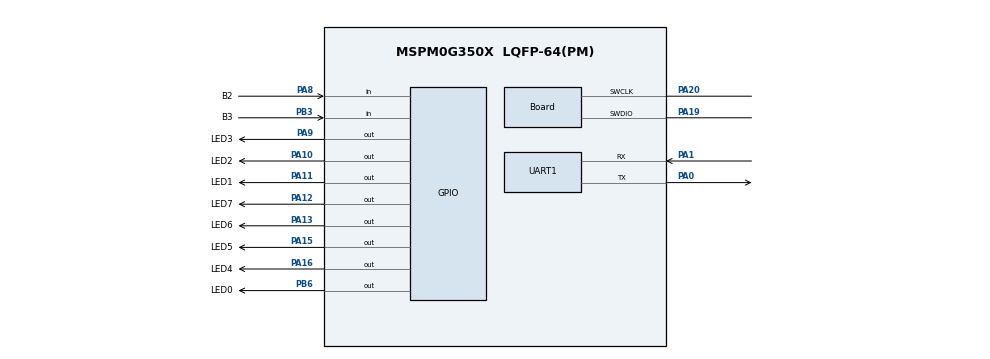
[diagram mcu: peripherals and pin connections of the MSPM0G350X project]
/**
 * @cliArgs --device "MSPM0G350X" --part "Default" --package "LQFP-64(PM)" --product "mspm0_sdk@2.05.01.01"
 * @versions {"tool":"1.24.0+4110"}
 */

/**
 * Import the modules used in this configuration.
 */
const ADC12  = scripting.addModule("/ti/driverlib/ADC12", {}, false);
const ADC121 = ADC12.addInstance();
const GPIO   = scripting.addModule("/ti/driverlib/GPIO", {}, false);
const GPIO1  = GPIO.addInstance();
const GPIO2  = GPIO.addInstance();
const SYSCTL = scripting.addModule("/ti/driverlib/SYSCTL");
const TIMER  = scripting.addModule("/ti/driverlib/TIMER", {}, false);
const TIMER1 = TIMER.addInstance();
const UART   = scripting.addModule("/ti/driverlib/UART", {}, false);
const UART1  = UART.addInstance();

/**
 * Write custom configuration values to the imported modules.
 */
ADC121.$name                             = "ADC12_0";
ADC121.adcMem1chansel                    = "DL_ADC12_INPUT_CHAN_1";
ADC121.adcMem2chansel                    = "DL_ADC12_INPUT_CHAN_2";
ADC121.adcMem3chansel                    = "DL_ADC12_INPUT_CHAN_3";
ADC121.adcMem4chansel                    = "DL_ADC12_INPUT_CHAN_5";
ADC121.adcMem5chansel                    = "DL_ADC12_INPUT_CHAN_6";
ADC121.adcMem6chansel                    = "DL_ADC12_INPUT_CHAN_7";
ADC121.adcMem7chansel                    = "DL_ADC12_INPUT_CHAN_12";
ADC121.repeatMode                        = true;
ADC121.powerDownMode                     = "DL_ADC12_POWER_DOWN_MODE_MANUAL";
ADC121.configureDMA                      = true;
ADC121.enabledInterrupts                 = ["DL_ADC12_INTERRUPT_DMA_DONE"];
ADC121.samplingOperationMode             = "sequence";
ADC121.sampleTime0                       = "100ns";
ADC121.endAdd                            = 7;
ADC121.enableFIFO                        = true;
ADC121.sampCnt                           = 2;
ADC121.enabledDMATriggers                = ["DL_ADC12_DMA_MEM11_RESULT_LOADED","DL_ADC12_DMA_MEM3_RESULT_LOADED","DL_ADC12_DMA_MEM7_RESULT_LOADED"];
ADC121.trigSrc                           = "DL_ADC12_TRIG_SRC_EVENT";
ADC121.adcMem7trig                       = "DL_ADC12_TRIGGER_MODE_TRIGGER_NEXT";
ADC121.subChanID                         = 1;
ADC121.adcPin0Config.$name               = "ti_driverlib_gpio_GPIOPinGeneric2";
ADC121.DMA_CHANNEL.$name                 = "DMA_CH0";
ADC121.DMA_CHANNEL.configureTransferSize = true;
ADC121.DMA_CHANNEL.transferMode          = "FULL_CH_REPEAT_SINGLE";
ADC121.DMA_CHANNEL.addressMode           = "f2b";
ADC121.DMA_CHANNEL.transferSize          = 480;
ADC121.DMA_CHANNEL.peripheral.$assign    = "DMA_CH0";
ADC121.peripheral.$assign                = "ADC0";
ADC121.peripheral.adcPin0.$assign        = "PA27";
ADC121.peripheral.adcPin1.$assign        = "PA26";
ADC121.peripheral.adcPin2.$assign        = "PA25";
ADC121.peripheral.adcPin3.$assign        = "PA24";
ADC121.peripheral.adcPin5.$assign        = "PB24";
ADC121.peripheral.adcPin6.$assign        = "PB20";
ADC121.peripheral.adcPin7.$assign        = "PA22";
ADC121.peripheral.adcPin12.$assign       = "PA14";
ADC121.adcPin1Config.$name               = "ti_driverlib_gpio_GPIOPinGeneric3";
ADC121.adcPin2Config.$name               = "ti_driverlib_gpio_GPIOPinGeneric4";
ADC121.adcPin3Config.$name               = "ti_driverlib_gpio_GPIOPinGeneric5";
ADC121.adcPin5Config.$name               = "ti_driverlib_gpio_GPIOPinGeneric6";
ADC121.adcPin6Config.$name               = "ti_driverlib_gpio_GPIOPinGeneric7";
ADC121.adcPin7Config.$name               = "ti_driverlib_gpio_GPIOPinGeneric8";
ADC121.adcPin12Config.$name              = "ti_driverlib_gpio_GPIOPinGeneric9";

const Board                       = scripting.addModule("/ti/driverlib/Board", {}, false);
Board.peripheral.$assign          = "DEBUGSS";
Board.peripheral.swclkPin.$assign = "PA20";
Board.peripheral.swdioPin.$assign = "PA19";

GPIO1.$name                              = "KEY";
GPIO1.associatedPins.create(3);
GPIO1.associatedPins[0].$name            = "B2";
GPIO1.associatedPins[0].direction        = "INPUT";
GPIO1.associatedPins[0].assignedPort     = "PORTA";
GPIO1.associatedPins[0].assignedPin      = "8";
GPIO1.associatedPins[0].internalResistor = "PULL_UP";
GPIO1.associatedPins[0].pin.$assign      = "PA8";
GPIO1.associatedPins[1].$name            = "B3";
GPIO1.associatedPins[1].direction        = "INPUT";
GPIO1.associatedPins[1].internalResistor = "PULL_UP";
GPIO1.associatedPins[1].assignedPort     = "PORTB";
GPIO1.associatedPins[1].assignedPin      = "3";
GPIO1.associatedPins[1].pin.$assign      = "PB3";
GPIO1.associatedPins[2].$name            = "PB21";
GPIO1.associatedPins[2].direction        = "INPUT";
GPIO1.associatedPins[2].assignedPort     = "PORTB";
GPIO1.associatedPins[2].assignedPin      = "21";
GPIO1.associatedPins[2].internalResistor = "PULL_UP";

GPIO2.$name                          = "LED";
GPIO2.associatedPins.create(9);
GPIO2.associatedPins[0].$name        = "LED0";
GPIO2.associatedPins[0].assignedPort = "PORTB";
GPIO2.associatedPins[0].assignedPin  = "6";
GPIO2.associatedPins[0].pin.$assign  = "PB6";
GPIO2.associatedPins[1].$name        = "LED1";
GPIO2.associatedPins[1].assignedPort = "PORTA";
GPIO2.associatedPins[1].assignedPin  = "11";
GPIO2.associatedPins[1].pin.$assign  = "PA11";
GPIO2.associatedPins[2].assignedPort = "PORTA";
GPIO2.associatedPins[2].$name        = "LED2";
GPIO2.associatedPins[2].assignedPin  = "10";
GPIO2.associatedPins[2].pin.$assign  = "PA10";
GPIO2.associatedPins[3].$name        = "LED3";
GPIO2.associatedPins[3].assignedPort = "PORTA";
GPIO2.associatedPins[3].assignedPin  = "9";
GPIO2.associatedPins[3].pin.$assign  = "PA9";
GPIO2.associatedPins[4].$name        = "LED4";
GPIO2.associatedPins[4].assignedPort = "PORTA";
GPIO2.associatedPins[4].assignedPin  = "16";
GPIO2.associatedPins[4].pin.$assign  = "PA16";
GPIO2.associatedPins[5].$name        = "LED5";
GPIO2.associatedPins[5].assignedPort = "PORTA";
GPIO2.associatedPins[5].assignedPin  = "15";
GPIO2.associatedPins[5].pin.$assign  = "PA15";
GPIO2.associatedPins[6].$name        = "LED6";
GPIO2.associatedPins[6].assignedPort = "PORTA";
GPIO2.associatedPins[6].assignedPin  = "13";
GPIO2.associatedPins[6].pin.$assign  = "PA13";
GPIO2.associatedPins[7].$name        = "LED7";
GPIO2.associatedPins[7].assignedPort = "PORTA";
GPIO2.associatedPins[7].assignedPin  = "12";
GPIO2.associatedPins[7].pin.$assign  = "PA12";
GPIO2.associatedPins[8].$name        = "PB22";
GPIO2.associatedPins[8].assignedPort = "PORTB";
GPIO2.associatedPins[8].assignedPin  = "22";

SYSCTL.forceDefaultClkConfig = true;
SYSCTL.peripheral.$assign    = "SYSCTL";

TIMER1.$name                       = "TIMER_0";
TIMER1.timerMode                   = "PERIODIC";
TIMER1.timerStartTimer             = true;
TIMER1.event1PublisherChannel      = 1;
TIMER1.event1ControllerInterruptEn = ["ZERO_EVENT"];
TIMER1.timerPeriod                 = "2ms";
TIMER1.peripheral.$assign          = "TIMA0";

UART1.$name                    = "UART_0";
UART1.enabledInterrupts        = ["RX"];
UART1.uartClkDiv               = "8";
UART1.peripheral.$assign       = "UART0";
UART1.peripheral.rxPin.$assign = "PA1";
UART1.peripheral.txPin.$assign = "PA0";
UART1.txPinConfig.$name        = "ti_driverlib_gpio_GPIOPinGeneric0";
UART1.rxPinConfig.$name        = "ti_driverlib_gpio_GPIOPinGeneric1";

const ProjectConfig              = scripting.addModule("/ti/project_config/ProjectConfig", {}, false);
ProjectConfig.migrationCondition = true;

/**
 * Pinmux solution for unlocked pins/peripherals. This ensures that minor changes to the automatic solver in a future
 * version of the tool will not impact the pinmux you originally saw.  These lines can be completely deleted in order to
 * re-solve from scratch.
 */
GPIO1.associatedPins[2].pin.$suggestSolution = "PB21";
GPIO2.associatedPins[8].pin.$suggestSolution = "PB22";
